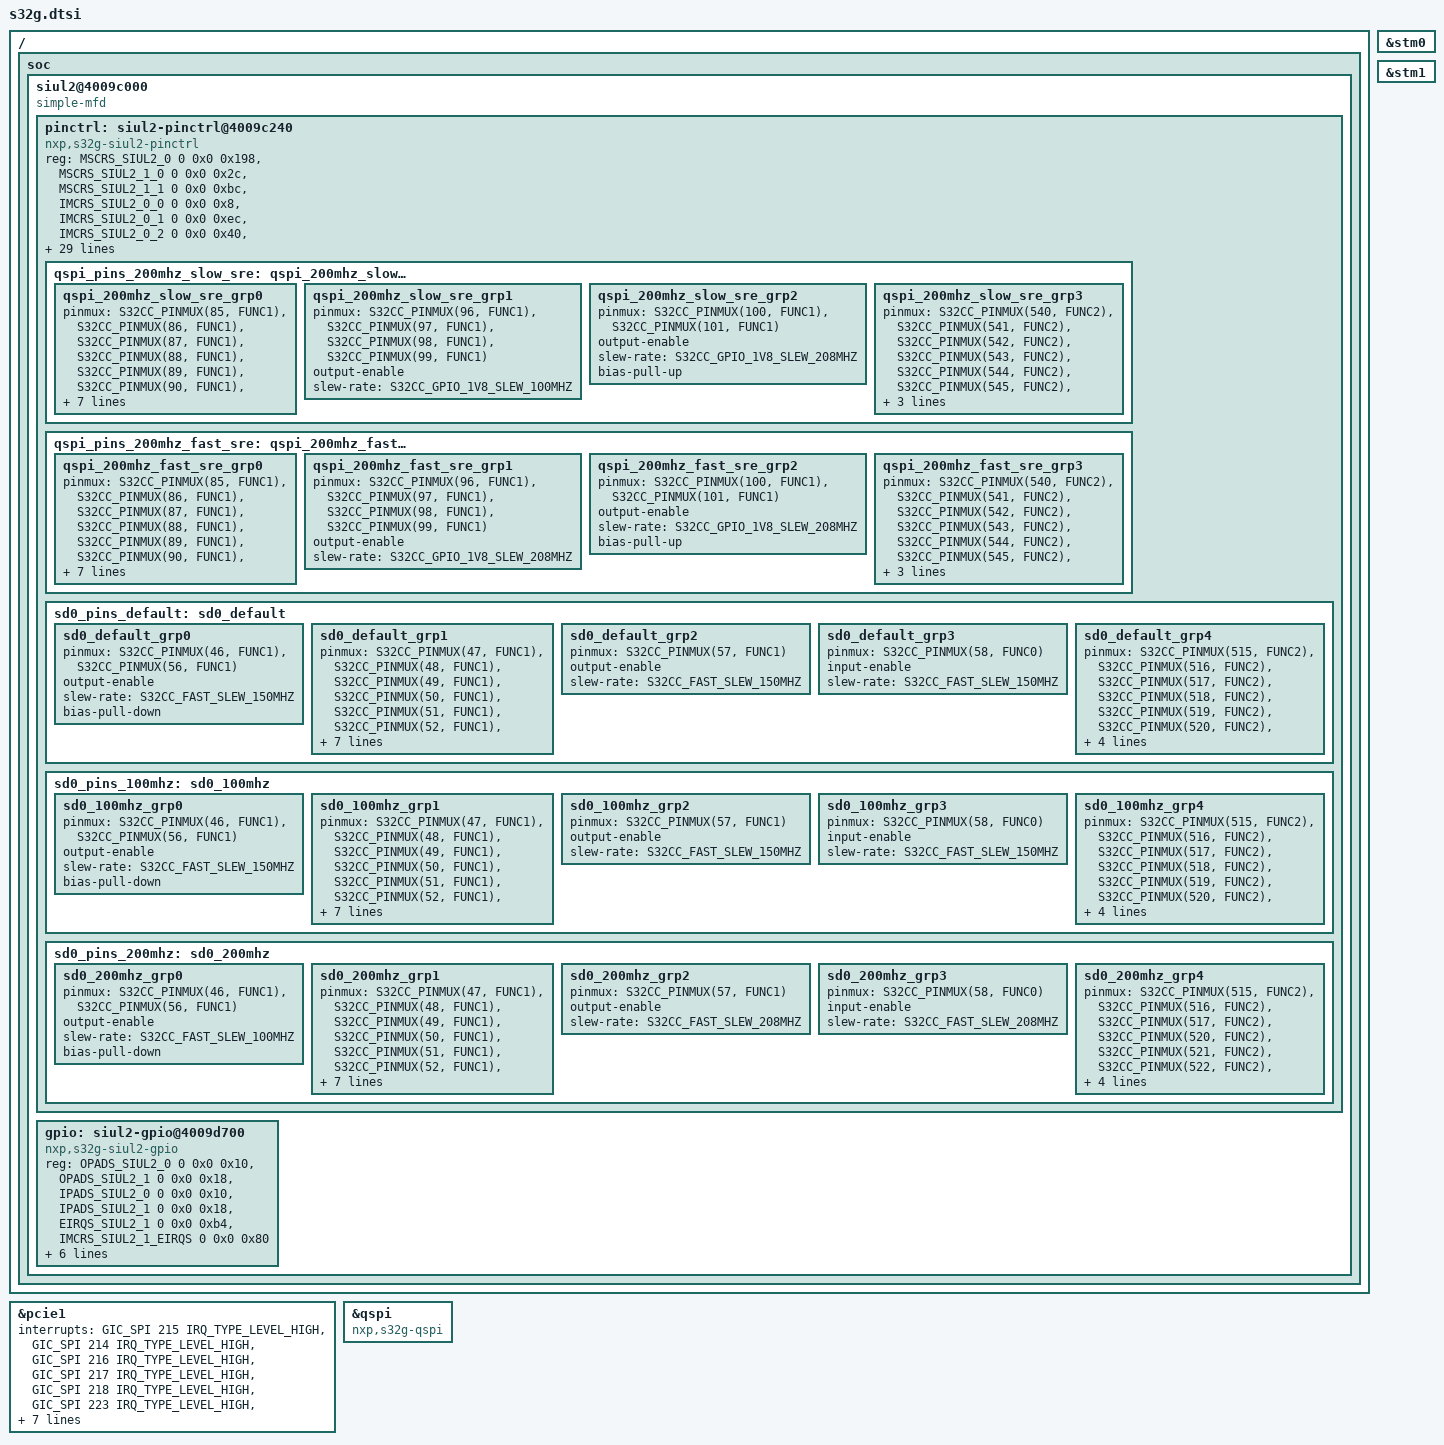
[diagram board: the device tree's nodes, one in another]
// SPDX-License-Identifier: GPL-2.0-or-later OR MIT
/*
 * Copyright 2019-2023 NXP
 */

#include "s32cc.dtsi"

/ {
	soc {
		siul2@4009c000 {
			compatible = "simple-mfd";
			status = "okay";
			#address-cells = <2>;
			#size-cells = <2>;

			/* MIDR */
			ranges = <MIDR_SIUL2_0 0x0 0x0 0x4009c000 0x0 0x10>,
				 <MIDR_SIUL2_1 0x0 0x0 0x44010000 0x0 0x10>,

				 /* MSCR 0-101 */
				 <MSCRS_SIUL2_0 0x0 0x0 0x4009c240 0x0 0x198>,
				 /* MSCR 112-122 */
				 <MSCRS_SIUL2_1_0 0x0 0x0 0x44010400 0x0 0x2c>,
				 /* MSCR 144-190 */
				 <MSCRS_SIUL2_1_1 0x0 0x0 0x44010480 0x0 0xbc>,

				 /* IMCR range 512 - 513 */
				 <IMCRS_SIUL2_0_0 0x0 0x0 0x4009ca40 0x0 0x8>,
				 /* IMCR range 515 - 573 */
				 <IMCRS_SIUL2_0_1 0x0 0x0 0x4009ca4c 0x0 0xec>,
				 /* IMCR range 580 - 595 */
				 <IMCRS_SIUL2_0_2 0x0 0x0 0x4009cb50 0x0 0x40>,
				 /* IMCR range 631 - 633 */
				 <IMCRS_SIUL2_1_0 0x0 0x0 0x44010c1c 0x0 0xc>,
				 /* IMCR range 640 - 641 */
				 <IMCRS_SIUL2_1_1 0x0 0x0 0x44010c40 0x0 0x8>,
				 /* IMCR range 655 - 663 */
				 <IMCRS_SIUL2_1_2 0x0 0x0 0x44010c7c 0x0 0x24>,
				 /* IMCR range 665 - 673 */
				 <IMCRS_SIUL2_1_3 0x0 0x0 0x44010ca4 0x0 0x24>,
				 /* IMCR range 717 - 724 */
				 <IMCRS_SIUL2_1_4 0x0 0x0 0x44010d74 0x0 0x20>,
				 /* IMCR range 736 - 737 */
				 <IMCRS_SIUL2_1_5 0x0 0x0 0x44010dc0 0x0 0x8>,
				 /* IMCR range 745 - 760 */
				 <IMCRS_SIUL2_1_6 0x0 0x0 0x44010de4 0x0 0x40>,
				 /* IMCR range 785 - 786 */
				 <IMCRS_SIUL2_1_7 0x0 0x0 0x44010e84 0x0 0x8>,
				 /* IMCR range 790 - 793 */
				 <IMCRS_SIUL2_1_8 0x0 0x0 0x44010e98 0x0 0x10>,
				 /* IMCR range 795 - 798 */
				 <IMCRS_SIUL2_1_9 0x0 0x0 0x44010eac 0x0 0x10>,
				 /* IMCR range 800 - 806 */
				 <IMCRS_SIUL2_1_10 0x0 0x0 0x44010ec0 0x0 0x1c>,
				 /* IMCR range 808 - 814 */
				 <IMCRS_SIUL2_1_11 0x0 0x0 0x44010ee0 0x0 0x1c>,
				 /* IMCR range 816 - 822 */
				 <IMCRS_SIUL2_1_12 0x0 0x0 0x44010f00 0x0 0x1c>,
				 /* IMCR range 824 - 826 */
				 <IMCRS_SIUL2_1_13 0x0 0x0 0x44010f20 0x0 0xc>,
				 /* IMCR range 828 - 828 */
				 <IMCRS_SIUL2_1_14 0x0 0x0 0x44010f30 0x0 0x4>,
				 /* IMCR range 830 - 830 */
				 <IMCRS_SIUL2_1_15 0x0 0x0 0x44010f38 0x0 0x4>,
				 /* IMCR range 834 - 852 */
				 <IMCRS_SIUL2_1_16 0x0 0x0 0x44010f48 0x0 0x4c>,
				 /* IMCR range 855 - 872 */
				 <IMCRS_SIUL2_1_17 0x0 0x0 0x44010f9c 0x0 0x48>,
				 /* IMCR range 875 - 892 */
				 <IMCRS_SIUL2_1_18 0x0 0x0 0x44010fec 0x0 0x48>,
				 /* IMCR range 895 - 905 */
				 <IMCRS_SIUL2_1_19 0x0 0x0 0x4401103c 0x0 0x2c>,
				 /* IMCR range 910 - 941 */
				 <IMCRS_SIUL2_1_EIRQS 0x0 0x0 0x44011078 0x0 0x80>,
				 /* IMCR range 942 - 945 */
				 <IMCRS_SIUL2_1_21 0x0 0x0 0x440110f8 0x0 0x10>,
				 /* IMCR range 979 - 982 */
				 <IMCRS_SIUL2_1_22 0x0 0x0 0x4401118c 0x0 0x10>,
				 /* IMCR range 985 - 987 */
				 <IMCRS_SIUL2_1_23 0x0 0x0 0x440111a4 0x0 0xc>,
				 /* IMCR range 990 - 992 */
				 <IMCRS_SIUL2_1_24 0x0 0x0 0x440111b8 0x0 0xc>,
				 /* IMCR range 995 - 997 */
				 <IMCRS_SIUL2_1_25 0x0 0x0 0x440111cc 0x0 0xc>,
				 /* IMCR range 1000 - 1002 */
				 <IMCRS_SIUL2_1_26 0x0 0x0 0x440111e0 0x0 0xc>,
				 /* IMCR range 1005 - 1007 */
				 <IMCRS_SIUL2_1_27 0x0 0x0 0x440111f4 0x0 0xc>,

				 /* Output pads */
				 <OPADS_SIUL2_0 0x0 0x0 0x4009d700 0x0 0x10>,
				 <OPADS_SIUL2_1 0x0 0x0 0x44011700 0x0 0x18>,

				 /* Input pads */
				 <IPADS_SIUL2_0 0x0 0x0 0x4009d740 0x0 0x10>,
				 <IPADS_SIUL2_1 0x0 0x0 0x44011740 0x0 0x18>,

				 /* EIRQs */
				 <EIRQS_SIUL2_1 0x0 0x0 0x44010010 0x0 0xb4>;

			pinctrl: siul2-pinctrl@4009c240 {
				compatible = "nxp,s32g-siul2-pinctrl",
					     "nxp,s32cc-siul2-pinctrl";
				#pinctrl-cells = <2>;

				reg = <MSCRS_SIUL2_0    0 0x0 0x198>,
				      <MSCRS_SIUL2_1_0  0 0x0 0x2c>,
				      <MSCRS_SIUL2_1_1  0 0x0 0xbc>,
				      <IMCRS_SIUL2_0_0  0 0x0 0x8>,
				      <IMCRS_SIUL2_0_1  0 0x0 0xec>,
				      <IMCRS_SIUL2_0_2  0 0x0 0x40>,
				      <IMCRS_SIUL2_1_0  0 0x0 0xc>,
				      <IMCRS_SIUL2_1_1  0 0x0 0x8>,
				      <IMCRS_SIUL2_1_2  0 0x0 0x24>,
				      <IMCRS_SIUL2_1_3  0 0x0 0x24>,
				      <IMCRS_SIUL2_1_4  0 0x0 0x20>,
				      <IMCRS_SIUL2_1_5  0 0x0 0x8>,
				      <IMCRS_SIUL2_1_6  0 0x0 0x40>,
				      <IMCRS_SIUL2_1_7  0 0x0 0x8>,
				      <IMCRS_SIUL2_1_8  0 0x0 0x10>,
				      <IMCRS_SIUL2_1_9  0 0x0 0x10>,
				      <IMCRS_SIUL2_1_10 0 0x0 0x1c>,
				      <IMCRS_SIUL2_1_11 0 0x0 0x1c>,
				      <IMCRS_SIUL2_1_12 0 0x0 0x1c>,
				      <IMCRS_SIUL2_1_13 0 0x0 0xc>,
				      <IMCRS_SIUL2_1_14 0 0x0 0x4>,
				      <IMCRS_SIUL2_1_15 0 0x0 0x4>,
				      <IMCRS_SIUL2_1_16 0 0x0 0x4c>,
				      <IMCRS_SIUL2_1_17 0 0x0 0x48>,
				      <IMCRS_SIUL2_1_18 0 0x0 0x48>,
				      <IMCRS_SIUL2_1_19 0 0x0 0x2c>,
				      <IMCRS_SIUL2_1_21 0 0x0 0x10>,
				      <IMCRS_SIUL2_1_22 0 0x0 0x10>,
				      <IMCRS_SIUL2_1_23 0 0x0 0xc>,
				      <IMCRS_SIUL2_1_24 0 0x0 0xc>,
				      <IMCRS_SIUL2_1_25 0 0x0 0xc>,
				      <IMCRS_SIUL2_1_26 0 0x0 0xc>,
				      <IMCRS_SIUL2_1_27 0 0x0 0xc>;

				/* MSCR range */
				nxp,pins = <0   101
					    112 122
					    144 190
				/* IMCR range */
					    512 513
					    515 573
					    580 595
					    631 633
					    640 641
					    655 663
					    665 673
					    717 724
					    736 737
					    745 760
					    785 786
					    790 793
					    795 798
					    800 806
					    808 814
					    816 822
					    824 826
					    828 828
					    830 830
					    834 852
					    855 872
					    875 892
					    895 905
					    942 945
					    979 982
					    985 987
					    990 992
					    995 997
					    1000 1002
					    1005 1007>;
				status = "okay";
			};

			gpio: siul2-gpio@4009d700 {
				compatible = "nxp,s32g-siul2-gpio", "nxp,s32cc-siul2-gpio";

				reg = <OPADS_SIUL2_0        0    0x0 0x10>,
				      <OPADS_SIUL2_1        0    0x0 0x18>,
				      <IPADS_SIUL2_0        0    0x0 0x10>,
				      <IPADS_SIUL2_1        0    0x0 0x18>,
				      <EIRQS_SIUL2_1        0    0x0 0xb4>,
				      <IMCRS_SIUL2_1_EIRQS  0    0x0 0x80>;
				reg-names = "opads0", "opads1", "ipads0",
					    "ipads1", "eirqs", "eirq-imcrs";

				#gpio-cells = <2>;
				gpio-controller;
					/* GPIO 0-101 */
				gpio-ranges = <&pinctrl 0   0   102>,
					/* GPIO 112-190 */
					      <&pinctrl 112 112 79>;
				gpio-reserved-ranges = <102 10>,
						       <123 21>;

				interrupt-controller;
				#interrupt-cells = <2>;
				interrupts = <GIC_SPI 210 IRQ_TYPE_LEVEL_HIGH>;
				status = "okay";
			};
		};
	};
};

&pcie1 {
	interrupts =  <GIC_SPI 215 IRQ_TYPE_LEVEL_HIGH>,
			<GIC_SPI 214 IRQ_TYPE_LEVEL_HIGH>,
			<GIC_SPI 216 IRQ_TYPE_LEVEL_HIGH>,
			<GIC_SPI 217 IRQ_TYPE_LEVEL_HIGH>,
			<GIC_SPI 218 IRQ_TYPE_LEVEL_HIGH>,
			<GIC_SPI 223 IRQ_TYPE_LEVEL_HIGH>,
			<GIC_SPI 224 IRQ_TYPE_LEVEL_HIGH>,
			<GIC_SPI 225 IRQ_TYPE_LEVEL_HIGH>;
	interrupt-names = "link_req_stat", "dma", "msi",
			"phy_link_down", "phy_link_up", "misc",
			"pcs", "tlp_req_no_comp";
	#interrupt-cells = <1>;
	interrupt-map-mask = <0 0 0 0x7>;
	interrupt-map = <0 0 0 1 &gic 0 0 0 219 4>,
			<0 0 0 2 &gic 0 0 0 220 4>,
			<0 0 0 3 &gic 0 0 0 221 4>,
			<0 0 0 4 &gic 0 0 0 222 4>;
	msi-parent = <&gic>;
};

&pinctrl {
	qspi_pins_200mhz_slow_sre: qspi_200mhz_slow_sre {
		qspi_200mhz_slow_sre_grp0 {
			pinmux = <S32CC_PINMUX(85, FUNC1)>,
				 <S32CC_PINMUX(86, FUNC1)>,
				 <S32CC_PINMUX(87, FUNC1)>,
				 <S32CC_PINMUX(88, FUNC1)>,
				 <S32CC_PINMUX(89, FUNC1)>,
				 <S32CC_PINMUX(90, FUNC1)>,
				 <S32CC_PINMUX(91, FUNC1)>,
				 <S32CC_PINMUX(92, FUNC1)>,
				 <S32CC_PINMUX(93, FUNC1)>;
			output-enable;
			input-enable;
			slew-rate = <S32CC_GPIO_1V8_SLEW_208MHZ>;
			bias-pull-down;
		};

		qspi_200mhz_slow_sre_grp1 {
			pinmux = <S32CC_PINMUX(96, FUNC1)>,
				 <S32CC_PINMUX(97, FUNC1)>,
				 <S32CC_PINMUX(98, FUNC1)>,
				 <S32CC_PINMUX(99, FUNC1)>;
			output-enable;
			/*
			 * Split SRE configuration SRE[2:0]=110
			 * for CLK and SRE[2:0]=000 for Data
			 */
			slew-rate = <S32CC_GPIO_1V8_SLEW_100MHZ>;
		};

		qspi_200mhz_slow_sre_grp2 {
			pinmux = <S32CC_PINMUX(100, FUNC1)>,
				 <S32CC_PINMUX(101, FUNC1)>;
			output-enable;
			slew-rate = <S32CC_GPIO_1V8_SLEW_208MHZ>;
			bias-pull-up;
		};

		qspi_200mhz_slow_sre_grp3 {
			pinmux = <S32CC_PINMUX(540, FUNC2)>,
				 <S32CC_PINMUX(541, FUNC2)>,
				 <S32CC_PINMUX(542, FUNC2)>,
				 <S32CC_PINMUX(543, FUNC2)>,
				 <S32CC_PINMUX(544, FUNC2)>,
				 <S32CC_PINMUX(545, FUNC2)>,
				 <S32CC_PINMUX(546, FUNC2)>,
				 <S32CC_PINMUX(547, FUNC2)>,
				 <S32CC_PINMUX(548, FUNC2)>;
		};
	};

	qspi_pins_200mhz_fast_sre: qspi_200mhz_fast_sre {
		qspi_200mhz_fast_sre_grp0 {
			pinmux = <S32CC_PINMUX(85, FUNC1)>,
				 <S32CC_PINMUX(86, FUNC1)>,
				 <S32CC_PINMUX(87, FUNC1)>,
				 <S32CC_PINMUX(88, FUNC1)>,
				 <S32CC_PINMUX(89, FUNC1)>,
				 <S32CC_PINMUX(90, FUNC1)>,
				 <S32CC_PINMUX(91, FUNC1)>,
				 <S32CC_PINMUX(92, FUNC1)>,
				 <S32CC_PINMUX(93, FUNC1)>;
			output-enable;
			input-enable;
			slew-rate = <S32CC_GPIO_1V8_SLEW_208MHZ>;
			bias-pull-down;
		};

		qspi_200mhz_fast_sre_grp1 {
			pinmux = <S32CC_PINMUX(96, FUNC1)>,
				 <S32CC_PINMUX(97, FUNC1)>,
				 <S32CC_PINMUX(98, FUNC1)>,
				 <S32CC_PINMUX(99, FUNC1)>;
			output-enable;
			/*
			 * Single SRE configuration SRE[2:0]=000
			 * for both Data & CLK
			 */
			slew-rate = <S32CC_GPIO_1V8_SLEW_208MHZ>;
		};

		qspi_200mhz_fast_sre_grp2 {
			pinmux = <S32CC_PINMUX(100, FUNC1)>,
				 <S32CC_PINMUX(101, FUNC1)>;
			output-enable;
			slew-rate = <S32CC_GPIO_1V8_SLEW_208MHZ>;
			bias-pull-up;
		};

		qspi_200mhz_fast_sre_grp3 {
			pinmux = <S32CC_PINMUX(540, FUNC2)>,
				 <S32CC_PINMUX(541, FUNC2)>,
				 <S32CC_PINMUX(542, FUNC2)>,
				 <S32CC_PINMUX(543, FUNC2)>,
				 <S32CC_PINMUX(544, FUNC2)>,
				 <S32CC_PINMUX(545, FUNC2)>,
				 <S32CC_PINMUX(546, FUNC2)>,
				 <S32CC_PINMUX(547, FUNC2)>,
				 <S32CC_PINMUX(548, FUNC2)>;
		};
	};

	sd0_pins_default: sd0_default {
		sd0_default_grp0 {
			pinmux = <S32CC_PINMUX(46, FUNC1)>,
				 <S32CC_PINMUX(56, FUNC1)>;
			output-enable;
			slew-rate = <S32CC_FAST_SLEW_150MHZ>;
			bias-pull-down;
		};

		sd0_default_grp1 {
			pinmux = <S32CC_PINMUX(47, FUNC1)>,
				 <S32CC_PINMUX(48, FUNC1)>,
				 <S32CC_PINMUX(49, FUNC1)>,
				 <S32CC_PINMUX(50, FUNC1)>,
				 <S32CC_PINMUX(51, FUNC1)>,
				 <S32CC_PINMUX(52, FUNC1)>,
				 <S32CC_PINMUX(53, FUNC1)>,
				 <S32CC_PINMUX(54, FUNC1)>,
				 <S32CC_PINMUX(55, FUNC1)>;
			output-enable;
			input-enable;
			slew-rate = <S32CC_FAST_SLEW_150MHZ>;
			bias-pull-up;
		};

		sd0_default_grp2 {
			pinmux = <S32CC_PINMUX(57, FUNC1)>;
			output-enable;
			slew-rate = <S32CC_FAST_SLEW_150MHZ>;
		};

		sd0_default_grp3 {
			pinmux = <S32CC_PINMUX(58, FUNC0)>;
			input-enable;
			slew-rate = <S32CC_FAST_SLEW_150MHZ>;
		};

		sd0_default_grp4 {
			pinmux = <S32CC_PINMUX(515, FUNC2)>,
				 <S32CC_PINMUX(516, FUNC2)>,
				 <S32CC_PINMUX(517, FUNC2)>,
				 <S32CC_PINMUX(518, FUNC2)>,
				 <S32CC_PINMUX(519, FUNC2)>,
				 <S32CC_PINMUX(520, FUNC2)>,
				 <S32CC_PINMUX(521, FUNC2)>,
				 <S32CC_PINMUX(522, FUNC2)>,
				 <S32CC_PINMUX(523, FUNC2)>,
				 <S32CC_PINMUX(524, FUNC2)>;
		};

	};

	sd0_pins_100mhz: sd0_100mhz {
		sd0_100mhz_grp0 {
			pinmux = <S32CC_PINMUX(46, FUNC1)>,
				 <S32CC_PINMUX(56, FUNC1)>;
			output-enable;
			slew-rate = <S32CC_FAST_SLEW_150MHZ>;
			bias-pull-down;
		};

		sd0_100mhz_grp1 {
			pinmux = <S32CC_PINMUX(47, FUNC1)>,
				 <S32CC_PINMUX(48, FUNC1)>,
				 <S32CC_PINMUX(49, FUNC1)>,
				 <S32CC_PINMUX(50, FUNC1)>,
				 <S32CC_PINMUX(51, FUNC1)>,
				 <S32CC_PINMUX(52, FUNC1)>,
				 <S32CC_PINMUX(53, FUNC1)>,
				 <S32CC_PINMUX(54, FUNC1)>,
				 <S32CC_PINMUX(55, FUNC1)>;
			output-enable;
			input-enable;
			slew-rate = <S32CC_FAST_SLEW_150MHZ>;
			bias-pull-up;
		};

		sd0_100mhz_grp2 {
			pinmux = <S32CC_PINMUX(57, FUNC1)>;
			output-enable;
			slew-rate = <S32CC_FAST_SLEW_150MHZ>;
		};

		sd0_100mhz_grp3 {
			pinmux = <S32CC_PINMUX(58, FUNC0)>;
			input-enable;
			slew-rate = <S32CC_FAST_SLEW_150MHZ>;
		};

		sd0_100mhz_grp4 {
			pinmux = <S32CC_PINMUX(515, FUNC2)>,
				 <S32CC_PINMUX(516, FUNC2)>,
				 <S32CC_PINMUX(517, FUNC2)>,
				 <S32CC_PINMUX(518, FUNC2)>,
				 <S32CC_PINMUX(519, FUNC2)>,
				 <S32CC_PINMUX(520, FUNC2)>,
				 <S32CC_PINMUX(521, FUNC2)>,
				 <S32CC_PINMUX(522, FUNC2)>,
				 <S32CC_PINMUX(523, FUNC2)>,
				 <S32CC_PINMUX(524, FUNC2)>;
		};
	};

	sd0_pins_200mhz: sd0_200mhz {
		sd0_200mhz_grp0 {
			pinmux = <S32CC_PINMUX(46, FUNC1)>,
				 <S32CC_PINMUX(56, FUNC1)>;
			output-enable;
			slew-rate = <S32CC_FAST_SLEW_100MHZ>;
			bias-pull-down;
		};

		sd0_200mhz_grp1 {
			pinmux = <S32CC_PINMUX(47, FUNC1)>,
				 <S32CC_PINMUX(48, FUNC1)>,
				 <S32CC_PINMUX(49, FUNC1)>,
				 <S32CC_PINMUX(50, FUNC1)>,
				 <S32CC_PINMUX(51, FUNC1)>,
				 <S32CC_PINMUX(52, FUNC1)>,
				 <S32CC_PINMUX(53, FUNC1)>,
				 <S32CC_PINMUX(54, FUNC1)>,
				 <S32CC_PINMUX(55, FUNC1)>;
			output-enable;
			input-enable;
			slew-rate = <S32CC_FAST_SLEW_208MHZ>;
			bias-pull-up;
		};

		sd0_200mhz_grp2 {
			pinmux = <S32CC_PINMUX(57, FUNC1)>;
			output-enable;
			slew-rate = <S32CC_FAST_SLEW_208MHZ>;
		};

		sd0_200mhz_grp3 {
			pinmux = <S32CC_PINMUX(58, FUNC0)>;
			input-enable;
			slew-rate = <S32CC_FAST_SLEW_208MHZ>;
		};

		sd0_200mhz_grp4 {
			pinmux = <S32CC_PINMUX(515, FUNC2)>,
				 <S32CC_PINMUX(516, FUNC2)>,
				 <S32CC_PINMUX(517, FUNC2)>,
				 <S32CC_PINMUX(520, FUNC2)>,
				 <S32CC_PINMUX(521, FUNC2)>,
				 <S32CC_PINMUX(522, FUNC2)>,
				 <S32CC_PINMUX(523, FUNC2)>,
				 <S32CC_PINMUX(519, FUNC2)>,
				 <S32CC_PINMUX(518, FUNC2)>,
				 <S32CC_PINMUX(524, FUNC2)>;
		};
	};
};

&qspi {
	compatible = "nxp,s32g-qspi";
};

&stm0 {
	status = "okay";
};

&stm1 {
	status = "okay";
};
